AUTOSAR XML (schema 4-3-0)
package /ComponentTypes
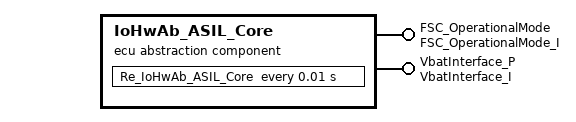
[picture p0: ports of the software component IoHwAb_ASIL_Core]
  ecu abstraction sw component type IoHwAb_ASIL_Core
    provide port FSC_OperationalMode: provided-com-specs=[{operation=FSC_OperationalMode, queue-length=1}, {operation=VbatInterface_P, queue-length=1}], provided-interface=FSC_OperationalMode_I
    provide port VbatInterface_P: provided-interface=VbatInterface_I
      provided-com-specs:
        operation=DobhsCtrlInterface_P_4, queue-length=1
        operation=DobhsCtrlInterface_P_5, queue-length=1
        operation=DobhsCtrlInterface_P_3, queue-length=1
        operation=DobhsCtrlInterface_P_2, queue-length=1
        operation=DobhsCtrlInterface_P_1, queue-length=1
        operation=FSC_OperationalMode, queue-length=1
        operation=VbatInterface_P, queue-length=1
    behavior IoHwAb_ASIL_Core_InternalBehavior
      timing event TMT_Re_IoHwAb_ASIL_Core: start-on-event=Re_IoHwAb_ASIL_Core, period=0.01
      runnable Re_IoHwAb_ASIL_Core
  swc implementation IoHwAb_ASIL_Core_Implementation: behavior=IoHwAb_ASIL_Core_InternalBehavior
